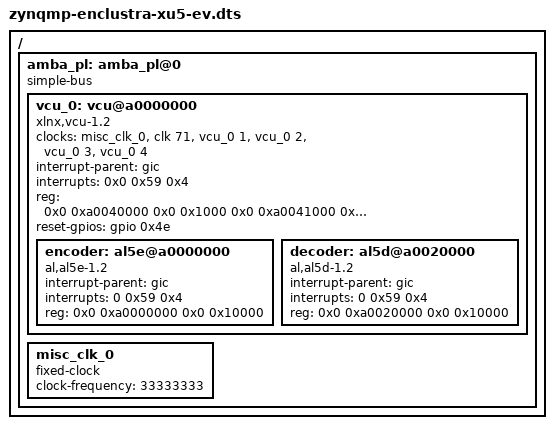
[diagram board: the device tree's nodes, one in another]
/*
 * dts file for Enclustra XU5 SOM
 *
 * (C) Copyright 2018, Xilinx, Inc.
 * (C) Copyright 2019, Enclustra
 *
 * This program is free software; you can redistribute it and/or
 * modify it under the terms of the GNU General Public License as
 * published by the Free Software Foundation; either version 2 of
 * the License, or (at your option) any later version.
 */

#include "zynqmp-enclustra-xu5.dts"

/ {
	amba_pl: amba_pl@0 {
		#address-cells = <0x2>;
		#size-cells = <0x2>;
		compatible = "simple-bus";
		ranges;

		vcu_0: vcu@a0000000 {
			#address-cells = <0x2>;
			#clock-cells = <0x1>;
			#size-cells = <0x2>;
			clock-names = "pll_ref", "aclk", "vcu_core_enc", "vcu_core_dec", "vcu_mcu_enc", "vcu_mcu_dec";
			clocks = <&misc_clk_0>, <&clk 71>, <&vcu_0 1>, <&vcu_0 2>, <&vcu_0 3>, <&vcu_0 4>;
			compatible = "xlnx,vcu-1.2", "xlnx,vcu";
			interrupt-names = "vcu_host_interrupt";
			interrupt-parent = <&gic>;
			interrupts = <0x0 0x59 0x4>;
			ranges;
			reg = <0x0 0xa0040000 0x0 0x1000 
					0x0 0xa0041000 0x0 0x1000>;
			reg-names = "vcu_slcr", "logicore";
			reset-gpios = <&gpio 0x4e 0x0>;

			encoder: al5e@a0000000 {
				compatible = "al,al5e-1.2", "al,al5e";
				interrupt-parent = <&gic>;
				interrupts = <0 0x59 0x4>;
				reg = <0x0 0xa0000000 0x0 0x10000>;
			};

			decoder: al5d@a0020000 {
				compatible = "al,al5d-1.2", "al,al5d";
				interrupt-parent = <&gic>;
				interrupts = <0 0x59 0x4>;
				reg = <0x0 0xa0020000 0x0 0x10000>;
			};
		};

		misc_clk_0: misc_clk_0 {
			#clock-cells = <0x0>;
			clock-frequency = <33333333>;
			compatible = "fixed-clock";
		};
	};
};
